# ESP32-H4 register map
Vendor: ESPRESSIF SYSTEMS (SHANGHAI) CO., LTD.; Series: ESP32 H-Series; File version: 1
CPU: RV32IMAC r0p0, little endian, no MPU, no FPU, 0 interrupt priority bits
Address unit: 32 bits
Registers are 32-bit, read-write, reset 0x0 unless marked. A register's access mark holds for its fields unless they carry their own. Offsets are from the block's base; [hi:lo] are bit positions; {n}, {i} and the like mark numbered series.

## CLINT — Core Local Interrupts
Base 0x20000000
Same registers: CLINT_OTHER_CORE 0x20010000
0x00 MSIP — Core-local machine software interrupt pending register
  [0] MSIP — Configures the pending status of the machine software interrupt.
0x4000 MTIMECMP 64-bit (reset mask 0xFFFFFFFF) — Core-local machine timer compare value
  [63:0] MTIMECMP — Represents the value to compare with the system counter.
0x4008 MTIMELOAD 64-bit (reset mask 0xFFFFFFFF) — Core-local machine timer load value
  [63:0] MTIMELOAD — Represents the value to be loaded to the system counter.
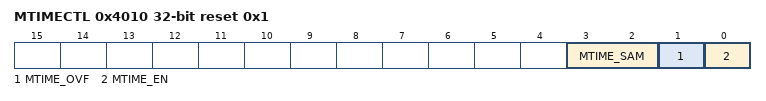
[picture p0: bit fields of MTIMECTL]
0x4010 MTIMECTL reset 0x1 — Core-local machine timer interrupt control/status register
  [3:2] MTIME_SAM — Configures the sampling mode of MTIME, to allow reading the 64-bit counter value consistently.
    0=NONE (No sampling); 1=SAMPLE_HIGH (Sample the upper half of the system counter when the lower half of MTIME is read); 2=SAMPLE_LOW (Sample the lower half of the system counter when the upper half of MTIME is read); 3=SAMPLE_OTHER (Sample the other half of the system counter when either half of MTIME is read)
  [1] MTIME_OVF — Set by hardware when the system counter reaches its maximum value. Software can clear this bit by writing 0 to it.
  [0] MTIME_EN — Configures whether to enable the system counter. This bit is implemented in the CLINT of core 0 only.
0xBFF8 MTIME 64-bit ro (reset mask 0xFFFFFFFF) — Core-local system counter value
  [63:0] MTIME — Represents the current value of the system counter.

## CLIC — Core Local Interrupt Controller
Base 0x20800000
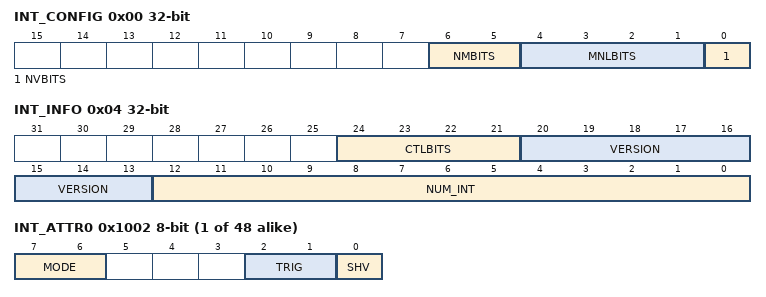
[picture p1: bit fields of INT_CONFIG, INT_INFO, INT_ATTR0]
0x00 INT_CONFIG
  [6:5] NMBITS — The effective number of bits in the privileged state.
  [4:1] MNLBITS — Machine mode interrupt priority effective digits, the maximum value is 8.
  [0] NVBITS — Hardware vector interrupt implementation flag bit.
0x04 INT_INFO ro
  [24:21] CTLBITS — The effective bits of priority in the CLICINTCTL register.
  [20:13] VERSION — The lower 4 bits are the modified version of the hardware implementation; the upper 4 bits are the CLIC architecture version information.
  [12:0] NUM_INT — The number of interrupt sources.
0x08 INT_THRESH
  [31:24] CPU_INT_THRESH — Threshold for machine mode interruption.
{0x1000+4i} INT_IP{i} (i=0..47) 8-bit — Interrupt pending register.
  [0] INT_IP — Interrupt pending bit.
{0x1001+4i} INT_IE{i} (i=0..47) 8-bit — Interrupt enable register.
  [0] INT_IE — Interrupt enable bit.
{0x1002+4i} INT_ATTR{i} (i=0..47) 8-bit access per field — Interrupt attribute register.
  [7:6] MODE ro — Privilege mode of the interrupt, hardwired to 0x3 (machine mode).
  [2:1] TRIG rw — Configures the trigger type and polarity of the interrupt.
    0=POSITIVE_LEVEL (interrupt is positive level-triggered); 1=POSITIVE_EDGE (interrupt is positive edge-triggered); 2=NEGATIVE_LEVEL (interrupt is negative level-triggered); 3=NEGATIVE_EDGE (interrupt is negative edge-triggered)
  [0] SHV rw — Represents whether the interrupt is a hardware vector interrupt.
    0=SOFTWARE (Not hardware vectored. Upon taking this interrupt, the CPU will jump to the address configured in mtvec.); 1=HARDWARE (Hardware vectored. Upon taking this interrupt, the CPU will jump to the word address stored at (mtvt + 4*i) relative to the base address configured in mtvt.)
{0x1003+4i} INT_CTL{i} (i=0..47) 8-bit access per field — Interrupt level control register.
  [7:5] CTL rw — Configures the level and priority of the interrupt.

## ECC — ECC (ECC Hardware Accelerator)
Base 0x600A8000
0x0C MULT_INT_RAW ro — ECC raw interrupt status register
  [0] CALC_DONE — The raw interrupt status of the ECC_CALC_DONE_INT interrupt.
0x10 MULT_INT_ST ro — ECC masked interrupt status register
  [0] CALC_DONE — The masked interrupt status of the ECC_CALC_DONE_INT interrupt.
0x14 MULT_INT_ENA — ECC interrupt enable register
  [0] CALC_DONE — Write 1 to enable the ECC_CALC_DONE_INT interrupt.
0x18 MULT_INT_CLR wo — ECC interrupt clear register
  [0] CALC_DONE write-1-clears — Write 1 to clear the ECC_CALC_DONE_INT interrupt.
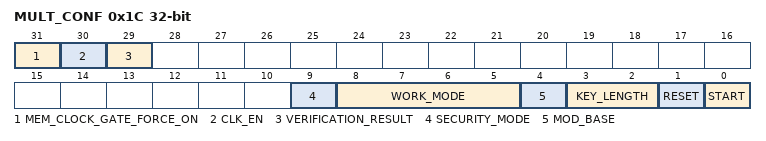
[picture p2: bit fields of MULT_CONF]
0x1C MULT_CONF access per field — ECC configuration register
  [31] MEM_CLOCK_GATE_FORCE_ON rw — Configures whether to force on ECC memory clock gate. \\ 0: No effect\\ 1: Force on\\
  [30] CLK_EN rw — Configures whether to force on register clock gate. \\ 0: No effect\\ 1: Force on\\
  [29] VERIFICATION_RESULT ro — Represents the verification result of ECC Accelerator, valid only when calculation is done.
  [9] SECURITY_MODE rw — Configures the security mode of ECC Accelerator.\\ 0: no secure function enabled.\\ 1: enable constant-time calculation in all point multiplication modes.\\
  [8:5] WORK_MODE rw — Configures the work mode of ECC Accelerator.\\ 0: Point Multi mode\\ 1: Reserved\\ 2: Point Verif mode\\ 3: Point Verif + Multi mode\\ 4: Jacobian Point Multi mode\\ 5: Reserved\\ 6: Jacobian Point Verif mode\\ 7: Point Verif + Jacobian Point Multi mode\\ 8: Mod Add mode\\ 9. Mod Sub mode\\ 10: Mod Multi mode\\ 11: Mod Div mode\\
  [4] MOD_BASE rw — Configures the mod base of mod operation, only valid in work_mode 8-11. \\ 0: n(order of curve)\\ 1: p(mod base of curve)\\
  [3:2] KEY_LENGTH rw — Configures the key length mode bit of ECC Accelerator. \\ 0: P-192\\ 1: P-256\\ 2: P-384\\ 3: SM2.\\
    0=P192 (P-192 elliptic curve); 1=P256 (P-256 elliptic curve); 2=P384 (P-384 elliptic curve)
  [1] RESET wo — Configures whether to reset ECC Accelerator. \\ 0: No effect\\ 1: Reset\\
  [0] START rw — Configures whether to start calculation of ECC Accelerator. This bit will be self-cleared after the calculation is done. \\ 0: No effect\\ 1: Start calculation of ECC Accelerator\\
0xFC DATE — Version control register
{0x100+4i} K_MEM{i} (i=0..7) access not given — The memory that stores k.
{0x130+4i} PX_MEM{i} (i=0..7) access not given — The memory that stores Px.
{0x160+4i} PY_MEM{i} (i=0..7) access not given — The memory that stores Py.
{0x190+4i} QX_MEM{i} (i=0..7) access not given — The memory that stores Qx.
{0x1C0+4i} QY_MEM{i} (i=0..7) access not given — The memory that stores Qy.
{0x1F0+4i} QZ_MEM{i} (i=0..7) access not given — The memory that stores Qz.
